# STM32H745_CM7 register map
File version: 2.0
CPU: CM7 r0p1, little endian, MPU, FPU, 4 interrupt priority bits
Registers are 32-bit, read-write, reset 0x0 unless marked. A register's access mark holds for its fields unless they carry their own. Offsets are from the block's base; [hi:lo] are bit positions; lines under a group give offsets from that group; {n}, {i} and the like mark numbered series.

## DFSDM — Digital filter for sigma delta modulators
Base 0x40017000
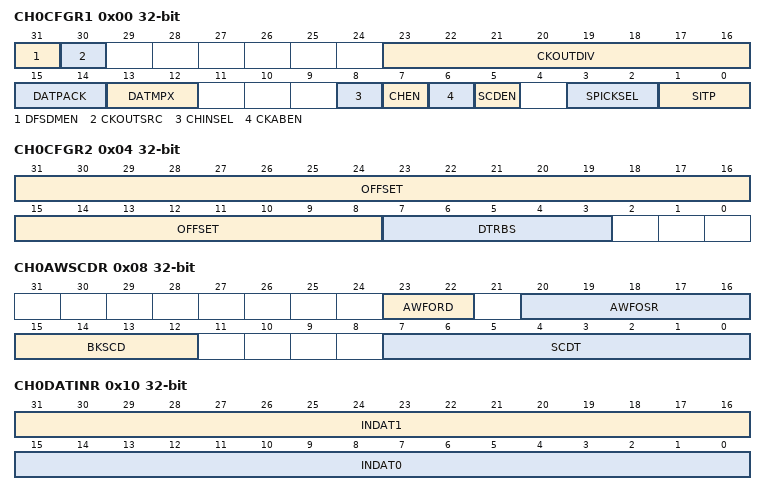
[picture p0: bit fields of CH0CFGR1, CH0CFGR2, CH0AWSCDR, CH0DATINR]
0x00 CH0CFGR1 — channel configuration y register
  [31] DFSDMEN, [30] CKOUTSRC, [23:16] CKOUTDIV, [15:14] DATPACK, [13:12] DATMPX, [8] CHINSEL, [7] CHEN, [6] CKABEN, [5] SCDEN, [3:2] SPICKSEL, [1:0] SITP
0x04 CH0CFGR2 — channel configuration y register
  [31:8] OFFSET, [7:3] DTRBS
0x08 CH0AWSCDR — analog watchdog and short-circuit detector register
  [23:22] AWFORD, [20:16] AWFOSR, [15:12] BKSCD, [7:0] SCDT
0x0C CH0WDATR — channel watchdog filter data register
  [15:0] WDATA
0x10 CH0DATINR — channel data input register
  [31:16] INDAT1, [15:0] INDAT0
{0x14+0x20*i} CH{i}DLYR (i=0..7) — channel y delay register
  [5:0] PLSSKP
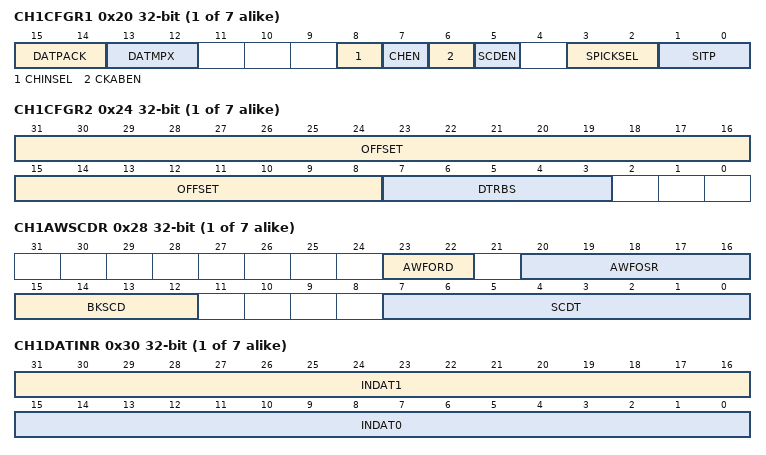
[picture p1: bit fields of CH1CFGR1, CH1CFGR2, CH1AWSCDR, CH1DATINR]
{0x0+0x20*i} CH{i}CFGR1 (i=1..7)
  [15:14] DATPACK, [13:12] DATMPX, [8] CHINSEL, [7] CHEN, [6] CKABEN, [5] SCDEN, [3:2] SPICKSEL, [1:0] SITP
{0x4+0x20*i} CH{i}CFGR2 (i=1..7)
  [31:8] OFFSET, [7:3] DTRBS
{0x8+0x20*i} CH{i}AWSCDR (i=1..7)
  [23:22] AWFORD, [20:16] AWFOSR, [15:12] BKSCD, [7:0] SCDT
{0xC+0x20*i} CH{i}WDATR (i=1..7)
  [15:0] WDATA
{0x10+0x20*i} CH{i}DATINR (i=1..7)
  [31:16] INDAT1, [15:0] INDAT0
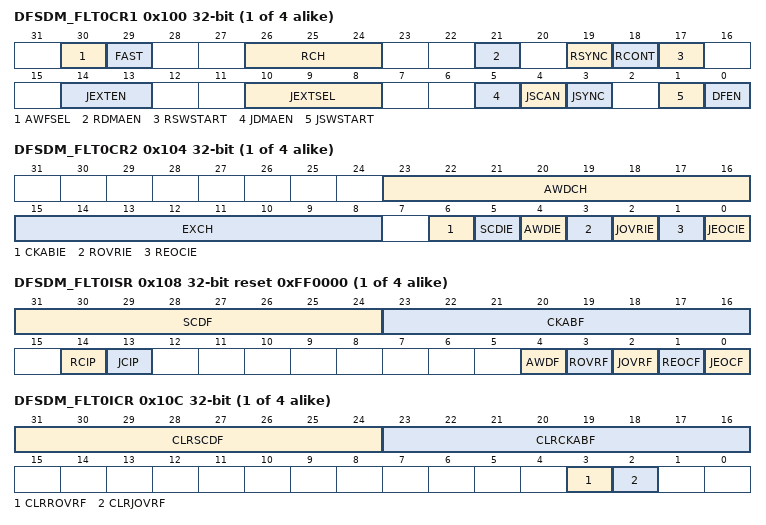
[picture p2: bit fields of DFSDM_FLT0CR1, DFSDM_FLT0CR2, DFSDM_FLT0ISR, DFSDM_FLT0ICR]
{0x100+0x80*i} DFSDM_FLT{i}CR1 (i=0..3) — control register 1
  [30] AWFSEL — Analog watchdog fast mode select
  [29] FAST — Fast conversion mode selection for regular conversions
  [26:24] RCH — Regular channel selection
  [21] RDMAEN — DMA channel enabled to read data for the regular conversion
  [19] RSYNC — Launch regular conversion synchronously with DFSDM0
  [18] RCONT — Continuous mode selection for regular conversions
  [17] RSWSTART — Software start of a conversion on the regular channel
  [14:13] JEXTEN — Trigger enable and trigger edge selection for injected conversions
  [10:8] JEXTSEL — Trigger signal selection for launching injected conversions
  [5] JDMAEN — DMA channel enabled to read data for the injected channel group
  [4] JSCAN — Scanning conversion mode for injected conversions
  [3] JSYNC — Launch an injected conversion synchronously with the DFSDM0 JSWSTART trigger
  [1] JSWSTART — Start a conversion of the injected group of channels
  [0] DFEN — DFSDM enable
{0x104+0x80*i} DFSDM_FLT{i}CR2 (i=0..3) — control register 2
  [23:16] AWDCH — Analog watchdog channel selection
  [15:8] EXCH — Extremes detector channel selection
  [6] CKABIE — Clock absence interrupt enable
  [5] SCDIE — Short-circuit detector interrupt enable
  [4] AWDIE — Analog watchdog interrupt enable
  [3] ROVRIE — Regular data overrun interrupt enable
  [2] JOVRIE — Injected data overrun interrupt enable
  [1] REOCIE — Regular end of conversion interrupt enable
  [0] JEOCIE — Injected end of conversion interrupt enable
{0x108+0x80*i} DFSDM_FLT{i}ISR ro reset 0xFF0000 (i=0..3) — interrupt and status register
  [31:24] SCDF — short-circuit detector flag
  [23:16] CKABF — Clock absence flag
  [14] RCIP — Regular conversion in progress status
  [13] JCIP — Injected conversion in progress status
  [4] AWDF — Analog watchdog
  [3] ROVRF — Regular conversion overrun flag
  [2] JOVRF — Injected conversion overrun flag
  [1] REOCF — End of regular conversion flag
  [0] JEOCF — End of injected conversion flag
{0x10C+0x80*i} DFSDM_FLT{i}ICR (i=0..3) — interrupt flag clear register
  [31:24] CLRSCDF — Clear the short-circuit detector flag
  [23:16] CLRCKABF — Clear the clock absence flag
  [3] CLRROVRF — Clear the regular conversion overrun flag
  [2] CLRJOVRF — Clear the injected conversion overrun flag
0x110 DFSDM_FLT0JCHGR reset 0x1 — injected channel group selection register
  [7:0] JCHG — Injected channel group selection
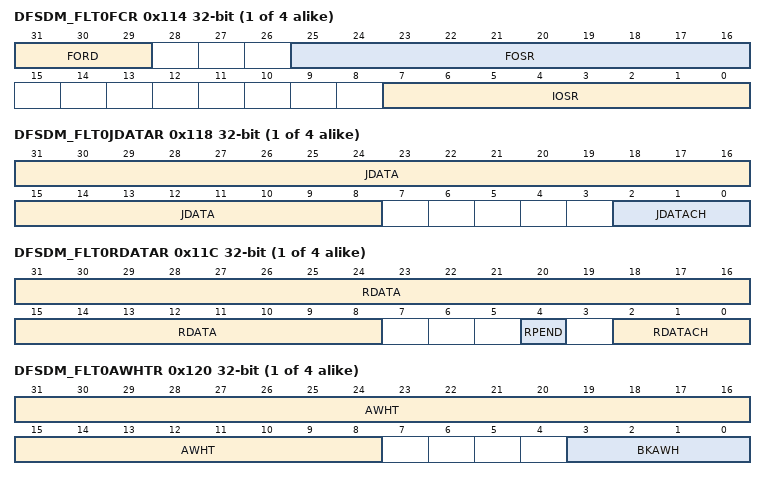
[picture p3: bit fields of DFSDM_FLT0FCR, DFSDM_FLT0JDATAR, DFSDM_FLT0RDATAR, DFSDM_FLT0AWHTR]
{0x114+0x80*i} DFSDM_FLT{i}FCR (i=0..3) — filter control register
  [31:29] FORD — Sinc filter order
  [25:16] FOSR — Sinc filter oversampling ratio (decimation rate)
  [7:0] IOSR — Integrator oversampling ratio (averaging length)
{0x118+0x80*i} DFSDM_FLT{i}JDATAR ro (i=0..3) — data register for injected group
  [31:8] JDATA — Injected group conversion data
  [2:0] JDATACH — Injected channel most recently converted
{0x11C+0x80*i} DFSDM_FLT{i}RDATAR ro (i=0..3) — data register for the regular channel
  [31:8] RDATA — Regular channel conversion data
  [4] RPEND — Regular channel pending data
  [2:0] RDATACH — Regular channel most recently converted
{0x120+0x80*i} DFSDM_FLT{i}AWHTR (i=0..3) — analog watchdog high threshold register
  [31:8] AWHT — Analog watchdog high threshold
  [3:0] BKAWH — Break signal assignment to analog watchdog high threshold event
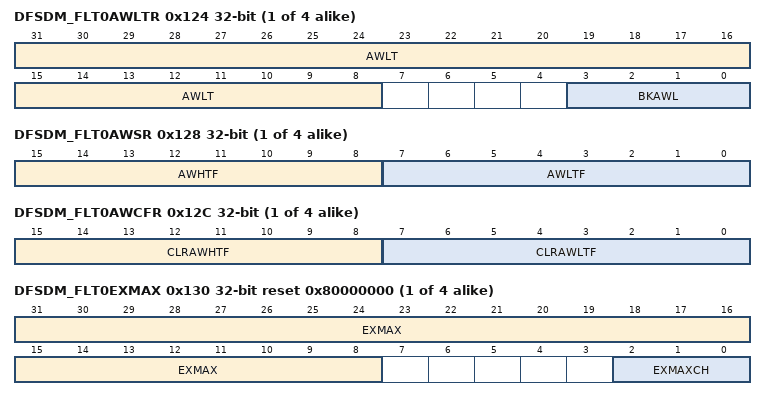
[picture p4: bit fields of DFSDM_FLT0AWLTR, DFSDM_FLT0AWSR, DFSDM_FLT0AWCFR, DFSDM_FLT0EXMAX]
{0x124+0x80*i} DFSDM_FLT{i}AWLTR (i=0..3) — analog watchdog low threshold register
  [31:8] AWLT — Analog watchdog low threshold
  [3:0] BKAWL — Break signal assignment to analog watchdog low threshold event
{0x128+0x80*i} DFSDM_FLT{i}AWSR ro (i=0..3) — analog watchdog status register
  [15:8] AWHTF — Analog watchdog high threshold flag
  [7:0] AWLTF — Analog watchdog low threshold flag
{0x12C+0x80*i} DFSDM_FLT{i}AWCFR (i=0..3) — analog watchdog clear flag register
  [15:8] CLRAWHTF — Clear the analog watchdog high threshold flag
  [7:0] CLRAWLTF — Clear the analog watchdog low threshold flag
{0x130+0x80*i} DFSDM_FLT{i}EXMAX ro reset 0x80000000 (i=0..3) — Extremes detector maximum register
  [31:8] EXMAX — Extremes detector maximum value
  [2:0] EXMAXCH — Extremes detector maximum data channel
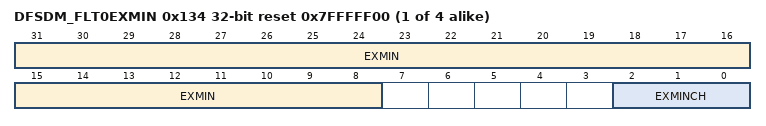
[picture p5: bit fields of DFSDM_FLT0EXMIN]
{0x134+0x80*i} DFSDM_FLT{i}EXMIN ro reset 0x7FFFFF00 (i=0..3) — Extremes detector minimum register
  [31:8] EXMIN
  [2:0] EXMINCH — Extremes detector minimum data channel
{0x138+0x80*i} DFSDM_FLT{i}CNVTIMR ro (i=0..3) — conversion timer register
  [31:4] CNVCNT — 28-bit timer counting conversion time t = CNVCNT[27:0] / fDFSDM_CKIN
0x190 DFSDM_FLT1CHGR reset 0x1 — injected channel group selection register
  [7:0] JCHG — Injected channel group selection
0x210 DFSDM_FLT2JCHGR reset 0x1 — injected channel group selection register
  [7:0] JCHG — Injected channel group selection
0x290 DFSDM_FLT3JCHGR reset 0x1 — injected channel group selection register
  [7:0] JCHG — Injected channel group selection
